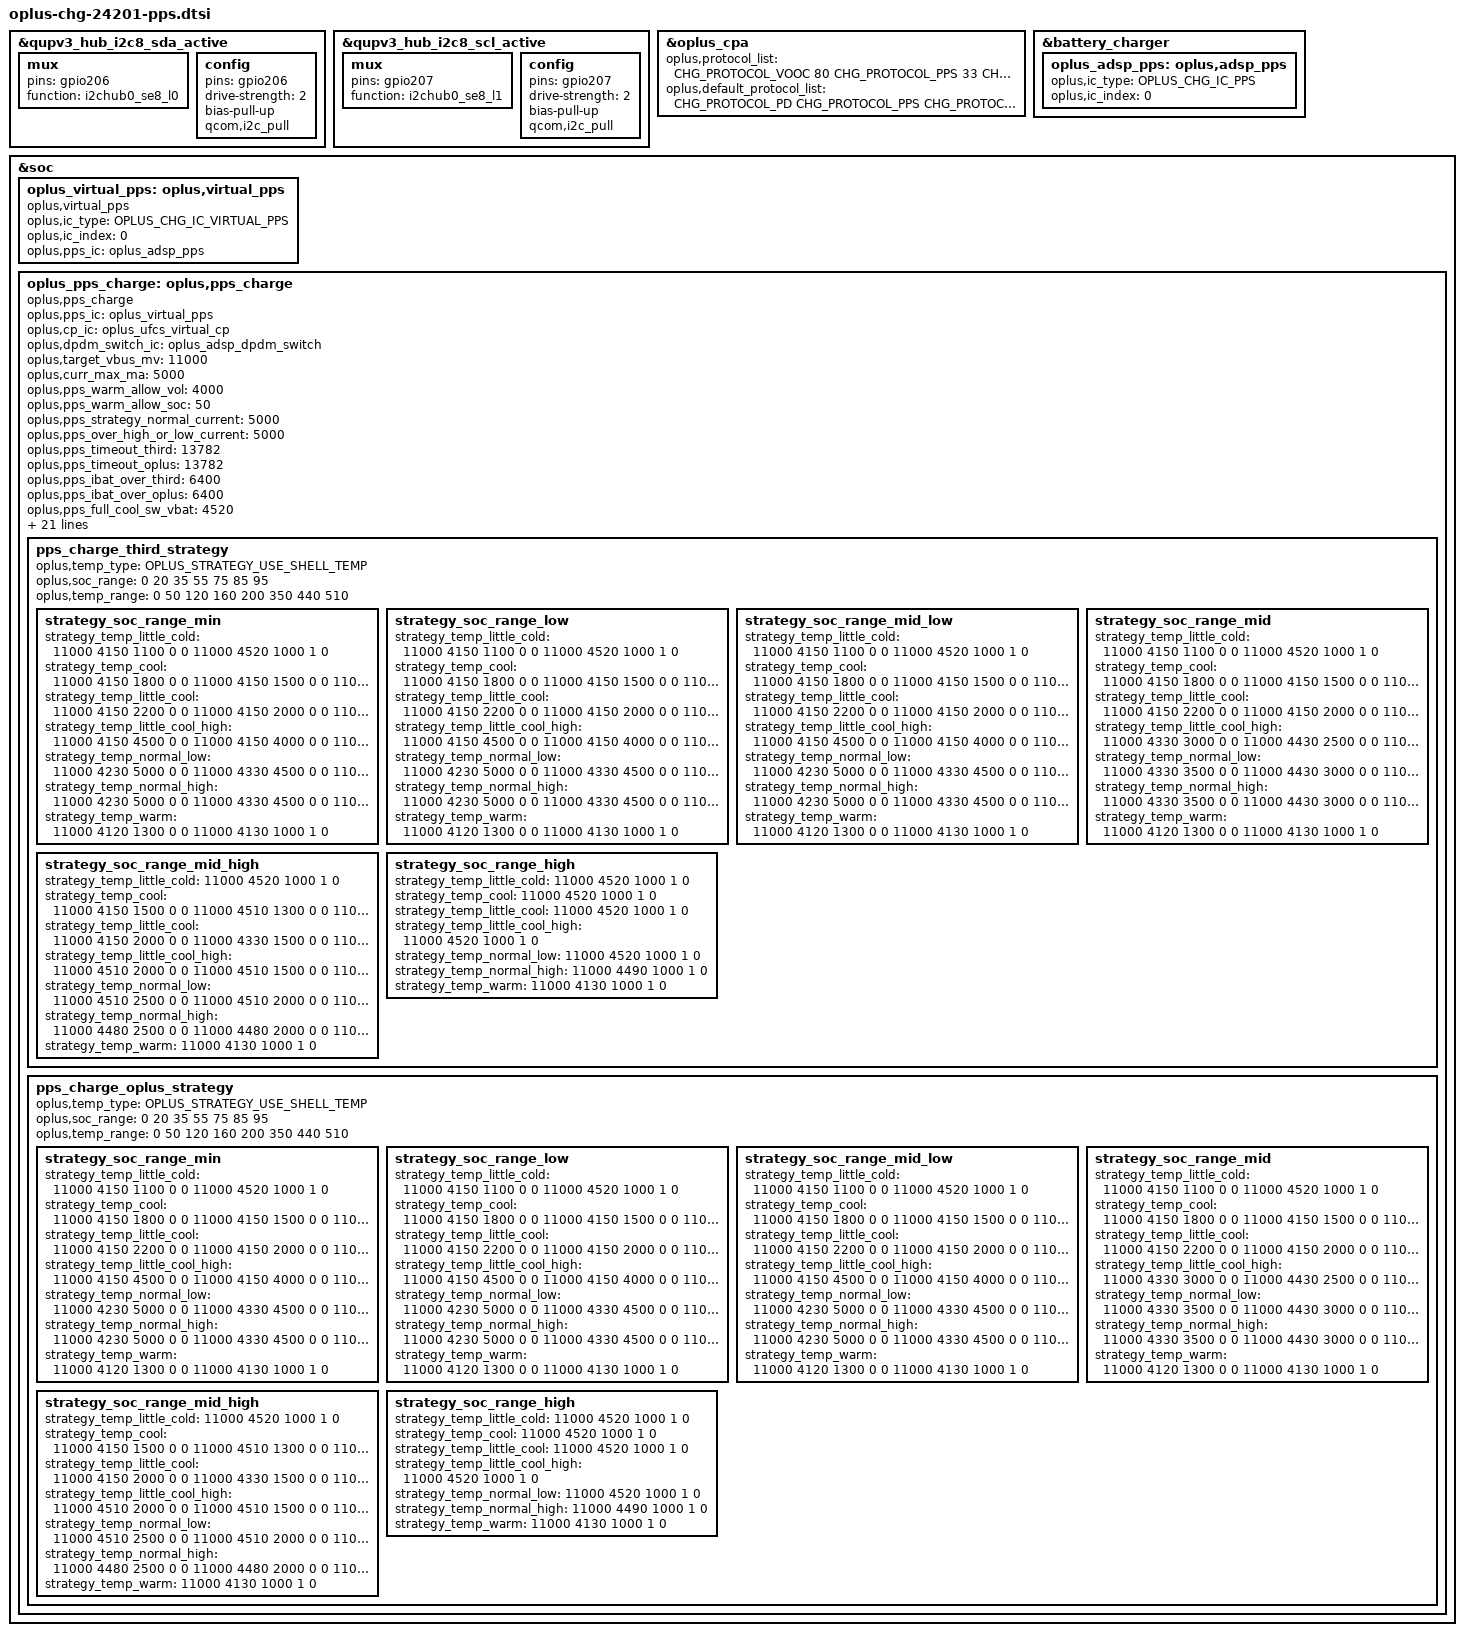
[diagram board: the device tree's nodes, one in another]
//ifdef OPLUS_FEATURE_CHG_BASIC
&qupv3_hub_i2c8_sda_active {
	mux {
		pins = "gpio206";
		function = "i2chub0_se8_l0";
	};

	config {
		pins = "gpio206";
		drive-strength = <2>;
		bias-pull-up;
		qcom,i2c_pull;
	};
};

&qupv3_hub_i2c8_scl_active {
	mux {
		pins = "gpio207";
		function = "i2chub0_se8_l1";
	};

	config {
		pins = "gpio207";
		drive-strength = <2>;
		bias-pull-up;
		qcom,i2c_pull;
	};
};

&oplus_cpa {
	/* format: <protocol_type power_w> */
	oplus,protocol_list = <CHG_PROTOCOL_VOOC 80
			       CHG_PROTOCOL_PPS  33
			       CHG_PROTOCOL_PD   18
			       CHG_PROTOCOL_QC   18>;
	oplus,default_protocol_list = <CHG_PROTOCOL_PD
				       CHG_PROTOCOL_PPS
				       CHG_PROTOCOL_VOOC>;
};

&battery_charger {
	oplus_adsp_pps: oplus,adsp_pps {
		oplus,ic_type = <OPLUS_CHG_IC_PPS>;
		oplus,ic_index = <0>;
	};
};

&soc {
	oplus_virtual_pps: oplus,virtual_pps {
		compatible = "oplus,virtual_pps";

		oplus,ic_type = <OPLUS_CHG_IC_VIRTUAL_PPS>;
		oplus,ic_index = <0>;
		oplus,pps_ic = <&oplus_adsp_pps>;
	};
	oplus_pps_charge: oplus,pps_charge {
		compatible = "oplus,pps_charge";
		oplus,pps_ic = <&oplus_virtual_pps>;
		oplus,cp_ic = <&oplus_ufcs_virtual_cp>;
		oplus,dpdm_switch_ic = <&oplus_adsp_dpdm_switch>;

		// oplus,impedance_unit = <&oplus_pps_impedance_unit>;

		oplus,target_vbus_mv = <11000>;
		oplus,curr_max_ma = <5000>;

		oplus,pps_warm_allow_vol = <4000>;
		oplus,pps_warm_allow_soc = <50>;
		oplus,pps_strategy_normal_current = <5000>;
		oplus,pps_over_high_or_low_current = <5000>;
		oplus,pps_timeout_third = <13782>;
		oplus,pps_timeout_oplus = <13782>;
		oplus,pps_ibat_over_third = <6400>;
		oplus,pps_ibat_over_oplus = <6400>;
		oplus,pps_full_cool_sw_vbat = <4520>;
		oplus,pps_full_normal_sw_vbat = <4520>;
		oplus,pps_full_normal_hw_vbat = <4560>;
		oplus,pps_full_ffc_vbat = <4560>;
		oplus,pps_full_warm_vbat = <4130>;
		oplus,pps_full_cool_sw_vbat_third = <4520>;
		oplus,pps_full_normal_sw_vbat_third= <4520>;
		oplus,pps_full_normal_hw_vbat_third = <4560>;
		oplus,pps_current_change_timeout = <100>;
		oplus,pps_r_default = <270 45 10 45 20 20 20>;
		oplus,pps_rmos_mohm = <5>;
		oplus,pps_r_limit = <150 100 80 70 30>;
		oplus,pps_strategy_batt_high_temp = <410 420 430 400 410 420>;
		oplus,pps_strategy_high_current = <3000 3000 2000 3000 3000 3000>;
		oplus,pps_little_cool_high_temp = <200>;
		oplus,curve_strategy_name = "pps_ufcs_curve_v2";
		oplus,pps_charge_strategy_soc = <0 20 35 55 75 85 95>;
		oplus,pps_charge_strategy_temp = <0 50 120 160 350 440 510>;

		pps_charge_third_strategy {
			oplus,temp_type = <OPLUS_STRATEGY_USE_SHELL_TEMP>;
			oplus,soc_range = <0 20 35 55 75 85 95>;
			oplus,temp_range = <0 50 120 160 200 350 440 510>;

			strategy_soc_range_min {
				strategy_temp_little_cold =	<11000 4150 1100 0 0
								11000 4520 1000 1 0>;
				strategy_temp_cool =		<11000 4150 1800 0 0
								11000 4150 1500 0 0
								11000 4510 1300 0 0
								11000 4520 1000 1 0>;
				strategy_temp_little_cool =	<11000 4150 2200 0 0
								11000 4150 2000 0 0
								11000 4330 1500 0 0
								11000 4330 1200 0 0
								11000 4520 1000 1 0>;
				strategy_temp_little_cool_high = <11000 4150 4500 0 0
								11000 4150 4000 0 0
								11000 4330 3500 0 0
								11000 4330 3000 0 0
								11000 4430 2500 0 0
								11000 4510 2000 0 0
								11000 4510 1500 0 0
								11000 4520 1000 1 0>;
				strategy_temp_normal_low =	<11000 4230 5000 0 0
								11000 4330 4500 0 0
								11000 4330 3500 0 0
								11000 4430 3000 0 0
								11000 4510 2500 0 0
								11000 4510 2000 0 0
								11000 4510 1800 0 0
								11000 4510 1500 0 0
								11000 4510 1300 0 0
								11000 4520 1000 1 0>;
				strategy_temp_normal_high =	<11000 4230 5000 0 0
								11000 4330 4500 0 0
								11000 4330 3500 0 0
								11000 4430 3000 0 0
								11000 4480 2500 0 0
								11000 4480 2000 0 0
								11000 4480 1800 0 0
								11000 4480 1500 0 0
								11000 4480 1300 0 0
								11000 4490 1000 1 0>;
				strategy_temp_warm =		<11000 4120 1300 0 0
								11000 4130 1000 1 0>;
			};
			strategy_soc_range_low {
				strategy_temp_little_cold =	<11000 4150 1100 0 0
								11000 4520 1000 1 0>;
				strategy_temp_cool =		<11000 4150 1800 0 0
								11000 4150 1500 0 0
								11000 4510 1300 0 0
								11000 4520 1000 1 0>;
				strategy_temp_little_cool =	<11000 4150 2200 0 0
								11000 4150 2000 0 0
								11000 4330 1500 0 0
								11000 4330 1200 0 0
								11000 4520 1000 1 0>;
				strategy_temp_little_cool_high = <11000 4150 4500 0 0
								11000 4150 4000 0 0
								11000 4330 3500 0 0
								11000 4330 3000 0 0
								11000 4430 2500 0 0
								11000 4510 2000 0 0
								11000 4510 1500 0 0
								11000 4520 1000 1 0>;
				strategy_temp_normal_low =	<11000 4230 5000 0 0
								11000 4330 4500 0 0
								11000 4330 3500 0 0
								11000 4430 3000 0 0
								11000 4510 2500 0 0
								11000 4510 2000 0 0
								11000 4510 1800 0 0
								11000 4510 1500 0 0
								11000 4510 1300 0 0
								11000 4520 1000 1 0>;
				strategy_temp_normal_high =	<11000 4230 5000 0 0
								11000 4330 4500 0 0
								11000 4330 3500 0 0
								11000 4430 3000 0 0
								11000 4480 2500 0 0
								11000 4480 2000 0 0
								11000 4480 1800 0 0
								11000 4480 1500 0 0
								11000 4480 1300 0 0
								11000 4490 1000 1 0>;
				strategy_temp_warm =		<11000 4120 1300 0 0
								11000 4130 1000 1 0>;
			};
			strategy_soc_range_mid_low {
				strategy_temp_little_cold =	<11000 4150 1100 0 0
								11000 4520 1000 1 0>;
				strategy_temp_cool =		<11000 4150 1800 0 0
								11000 4150 1500 0 0
								11000 4510 1300 0 0
								11000 4520 1000 1 0>;
				strategy_temp_little_cool =	<11000 4150 2200 0 0
								11000 4150 2000 0 0
								11000 4330 1500 0 0
								11000 4330 1200 0 0
								11000 4520 1000 1 0>;
				strategy_temp_little_cool_high = <11000 4150 4500 0 0
								11000 4150 4000 0 0
								11000 4330 3500 0 0
								11000 4330 3000 0 0
								11000 4430 2500 0 0
								11000 4510 2000 0 0
								11000 4510 1500 0 0
								11000 4520 1000 1 0>;
				strategy_temp_normal_low =	<11000 4230 5000 0 0
								11000 4330 4500 0 0
								11000 4330 3500 0 0
								11000 4430 3000 0 0
								11000 4510 2500 0 0
								11000 4510 2000 0 0
								11000 4510 1800 0 0
								11000 4510 1500 0 0
								11000 4510 1300 0 0
								11000 4520 1000 1 0>;
				strategy_temp_normal_high =	<11000 4230 5000 0 0
								11000 4330 4500 0 0
								11000 4330 3500 0 0
								11000 4430 3000 0 0
								11000 4480 2500 0 0
								11000 4480 2000 0 0
								11000 4480 1800 0 0
								11000 4480 1500 0 0
								11000 4480 1300 0 0
								11000 4490 1000 1 0>;
				strategy_temp_warm =		<11000 4120 1300 0 0
								11000 4130 1000 1 0>;
			};
			strategy_soc_range_mid {
				strategy_temp_little_cold =	<11000 4150 1100 0 0
								11000 4520 1000 1 0>;
				strategy_temp_cool =		<11000 4150 1800 0 0
								11000 4150 1500 0 0
								11000 4510 1300 0 0
								11000 4520 1000 1 0>;
				strategy_temp_little_cool =	<11000 4150 2200 0 0
								11000 4150 2000 0 0
								11000 4330 1500 0 0
								11000 4330 1200 0 0
								11000 4520 1000 1 0>;
				strategy_temp_little_cool_high = <11000 4330 3000 0 0
								11000 4430 2500 0 0
								11000 4510 2000 0 0
								11000 4510 1500 0 0
								11000 4520 1000 1 0>;
				strategy_temp_normal_low =	<11000 4330 3500 0 0
								11000 4430 3000 0 0
								11000 4510 2500 0 0
								11000 4510 2000 0 0
								11000 4510 1800 0 0
								11000 4510 1500 0 0
								11000 4510 1300 0 0
								11000 4520 1000 1 0>;
				strategy_temp_normal_high =	<11000 4330 3500 0 0
								11000 4430 3000 0 0
								11000 4480 2500 0 0
								11000 4480 2000 0 0
								11000 4480 1800 0 0
								11000 4480 1500 0 0
								11000 4480 1300 0 0
								11000 4490 1000 1 0>;
				strategy_temp_warm =		<11000 4120 1300 0 0
								11000 4130 1000 1 0>;
			};
			strategy_soc_range_mid_high {
				strategy_temp_little_cold =	<11000 4520 1000 1 0>;
				strategy_temp_cool =		<11000 4150 1500 0 0
								11000 4510 1300 0 0
								11000 4520 1000 1 0>;
				strategy_temp_little_cool =	<11000 4150 2000 0 0
								11000 4330 1500 0 0
								11000 4330 1200 0 0
								11000 4520 1000 1 0>;
				strategy_temp_little_cool_high = <11000 4510 2000 0 0
								11000 4510 1500 0 0
								11000 4520 1000 1 0>;
				strategy_temp_normal_low =	<11000 4510 2500 0 0
								11000 4510 2000 0 0
								11000 4510 1800 0 0
								11000 4510 1500 0 0
								11000 4510 1300 0 0
								11000 4520 1000 1 0>;
				strategy_temp_normal_high =	<11000 4480 2500 0 0
								11000 4480 2000 0 0
								11000 4480 1800 0 0
								11000 4480 1500 0 0
								11000 4480 1300 0 0
								11000 4490 1000 1 0>;
				strategy_temp_warm =		<11000 4130 1000 1 0>;
			};
			strategy_soc_range_high {
				strategy_temp_little_cold =	<11000 4520 1000 1 0>;
				strategy_temp_cool =		<11000 4520 1000 1 0>;
				strategy_temp_little_cool =	<11000 4520 1000 1 0>;
				strategy_temp_little_cool_high = <11000 4520 1000 1 0>;
				strategy_temp_normal_low =	<11000 4520 1000 1 0>;
				strategy_temp_normal_high =	<11000 4490 1000 1 0>;
				strategy_temp_warm =		<11000 4130 1000 1 0>;
			};
		};

		pps_charge_oplus_strategy {
			oplus,temp_type = <OPLUS_STRATEGY_USE_SHELL_TEMP>;
			oplus,soc_range = <0 20 35 55 75 85 95>;
			oplus,temp_range = <0 50 120 160 200 350 440 510>;

			strategy_soc_range_min {
				strategy_temp_little_cold =	<11000 4150 1100 0 0
								11000 4520 1000 1 0>;
				strategy_temp_cool =		<11000 4150 1800 0 0
								11000 4150 1500 0 0
								11000 4510 1300 0 0
								11000 4520 1000 1 0>;
				strategy_temp_little_cool =	<11000 4150 2200 0 0
								11000 4150 2000 0 0
								11000 4330 1500 0 0
								11000 4330 1200 0 0
								11000 4520 1000 1 0>;
				strategy_temp_little_cool_high = <11000 4150 4500 0 0
								11000 4150 4000 0 0
								11000 4330 3500 0 0
								11000 4330 3000 0 0
								11000 4430 2500 0 0
								11000 4510 2000 0 0
								11000 4510 1500 0 0
								11000 4520 1000 1 0>;
				strategy_temp_normal_low =	<11000 4230 5000 0 0
								11000 4330 4500 0 0
								11000 4330 3500 0 0
								11000 4430 3000 0 0
								11000 4510 2500 0 0
								11000 4510 2000 0 0
								11000 4510 1800 0 0
								11000 4510 1500 0 0
								11000 4510 1300 0 0
								11000 4520 1000 1 0>;
				strategy_temp_normal_high =	<11000 4230 5000 0 0
								11000 4330 4500 0 0
								11000 4330 3500 0 0
								11000 4430 3000 0 0
								11000 4480 2500 0 0
								11000 4480 2000 0 0
								11000 4480 1800 0 0
								11000 4480 1500 0 0
								11000 4480 1300 0 0
								11000 4490 1000 1 0>;
				strategy_temp_warm =		<11000 4120 1300 0 0
								11000 4130 1000 1 0>;
			};
			strategy_soc_range_low {
				strategy_temp_little_cold =	<11000 4150 1100 0 0
								11000 4520 1000 1 0>;
				strategy_temp_cool =		<11000 4150 1800 0 0
								11000 4150 1500 0 0
								11000 4510 1300 0 0
								11000 4520 1000 1 0>;
				strategy_temp_little_cool =	<11000 4150 2200 0 0
								11000 4150 2000 0 0
								11000 4330 1500 0 0
								11000 4330 1200 0 0
								11000 4520 1000 1 0>;
				strategy_temp_little_cool_high = <11000 4150 4500 0 0
								11000 4150 4000 0 0
								11000 4330 3500 0 0
								11000 4330 3000 0 0
								11000 4430 2500 0 0
								11000 4510 2000 0 0
								11000 4510 1500 0 0
								11000 4520 1000 1 0>;
				strategy_temp_normal_low =	<11000 4230 5000 0 0
								11000 4330 4500 0 0
								11000 4330 3500 0 0
								11000 4430 3000 0 0
								11000 4510 2500 0 0
								11000 4510 2000 0 0
								11000 4510 1800 0 0
								11000 4510 1500 0 0
								11000 4510 1300 0 0
								11000 4520 1000 1 0>;
				strategy_temp_normal_high =	<11000 4230 5000 0 0
								11000 4330 4500 0 0
								11000 4330 3500 0 0
								11000 4430 3000 0 0
								11000 4480 2500 0 0
								11000 4480 2000 0 0
								11000 4480 1800 0 0
								11000 4480 1500 0 0
								11000 4480 1300 0 0
								11000 4490 1000 1 0>;
				strategy_temp_warm =		<11000 4120 1300 0 0
								11000 4130 1000 1 0>;
			};
			strategy_soc_range_mid_low {
				strategy_temp_little_cold =	<11000 4150 1100 0 0
								11000 4520 1000 1 0>;
				strategy_temp_cool =		<11000 4150 1800 0 0
								11000 4150 1500 0 0
								11000 4510 1300 0 0
								11000 4520 1000 1 0>;
				strategy_temp_little_cool =	<11000 4150 2200 0 0
								11000 4150 2000 0 0
								11000 4330 1500 0 0
								11000 4330 1200 0 0
								11000 4520 1000 1 0>;
				strategy_temp_little_cool_high = <11000 4150 4500 0 0
								11000 4150 4000 0 0
								11000 4330 3500 0 0
								11000 4330 3000 0 0
								11000 4430 2500 0 0
								11000 4510 2000 0 0
								11000 4510 1500 0 0
								11000 4520 1000 1 0>;
				strategy_temp_normal_low =	<11000 4230 5000 0 0
								11000 4330 4500 0 0
								11000 4330 3500 0 0
								11000 4430 3000 0 0
								11000 4510 2500 0 0
								11000 4510 2000 0 0
								11000 4510 1800 0 0
								11000 4510 1500 0 0
								11000 4510 1300 0 0
								11000 4520 1000 1 0>;
				strategy_temp_normal_high =	<11000 4230 5000 0 0
								11000 4330 4500 0 0
								11000 4330 3500 0 0
								11000 4430 3000 0 0
								11000 4480 2500 0 0
								11000 4480 2000 0 0
								11000 4480 1800 0 0
								11000 4480 1500 0 0
								11000 4480 1300 0 0
								11000 4490 1000 1 0>;
				strategy_temp_warm =		<11000 4120 1300 0 0
								11000 4130 1000 1 0>;
			};
			strategy_soc_range_mid {
				strategy_temp_little_cold =	<11000 4150 1100 0 0
								11000 4520 1000 1 0>;
				strategy_temp_cool =		<11000 4150 1800 0 0
								11000 4150 1500 0 0
								11000 4510 1300 0 0
								11000 4520 1000 1 0>;
				strategy_temp_little_cool =	<11000 4150 2200 0 0
								11000 4150 2000 0 0
								11000 4330 1500 0 0
								11000 4330 1200 0 0
								11000 4520 1000 1 0>;
				strategy_temp_little_cool_high = <11000 4330 3000 0 0
								11000 4430 2500 0 0
								11000 4510 2000 0 0
								11000 4510 1500 0 0
								11000 4520 1000 1 0>;
				strategy_temp_normal_low =	<11000 4330 3500 0 0
								11000 4430 3000 0 0
								11000 4510 2500 0 0
								11000 4510 2000 0 0
								11000 4510 1800 0 0
								11000 4510 1500 0 0
								11000 4510 1300 0 0
								11000 4520 1000 1 0>;
				strategy_temp_normal_high =	<11000 4330 3500 0 0
								11000 4430 3000 0 0
								11000 4480 2500 0 0
								11000 4480 2000 0 0
								11000 4480 1800 0 0
								11000 4480 1500 0 0
								11000 4480 1300 0 0
								11000 4490 1000 1 0>;
				strategy_temp_warm =		<11000 4120 1300 0 0
								11000 4130 1000 1 0>;
			};
			strategy_soc_range_mid_high {
				strategy_temp_little_cold =	<11000 4520 1000 1 0>;
				strategy_temp_cool =		<11000 4150 1500 0 0
								11000 4510 1300 0 0
								11000 4520 1000 1 0>;
				strategy_temp_little_cool =	<11000 4150 2000 0 0
								11000 4330 1500 0 0
								11000 4330 1200 0 0
								11000 4520 1000 1 0>;
				strategy_temp_little_cool_high = <11000 4510 2000 0 0
								11000 4510 1500 0 0
								11000 4520 1000 1 0>;
				strategy_temp_normal_low =	<11000 4510 2500 0 0
								11000 4510 2000 0 0
								11000 4510 1800 0 0
								11000 4510 1500 0 0
								11000 4510 1300 0 0
								11000 4520 1000 1 0>;
				strategy_temp_normal_high =	<11000 4480 2500 0 0
								11000 4480 2000 0 0
								11000 4480 1800 0 0
								11000 4480 1500 0 0
								11000 4480 1300 0 0
								11000 4490 1000 1 0>;
				strategy_temp_warm =		<11000 4130 1000 1 0>;
			};
			strategy_soc_range_high {
				strategy_temp_little_cold =	<11000 4520 1000 1 0>;
				strategy_temp_cool =		<11000 4520 1000 1 0>;
				strategy_temp_little_cool =	<11000 4520 1000 1 0>;
				strategy_temp_little_cool_high = <11000 4520 1000 1 0>;
				strategy_temp_normal_low =	<11000 4520 1000 1 0>;
				strategy_temp_normal_high =	<11000 4490 1000 1 0>;
				strategy_temp_warm =		<11000 4130 1000 1 0>;
			};
		};
	};
};
//#endif OPLUS_FEATURE_CHG_BASIC
